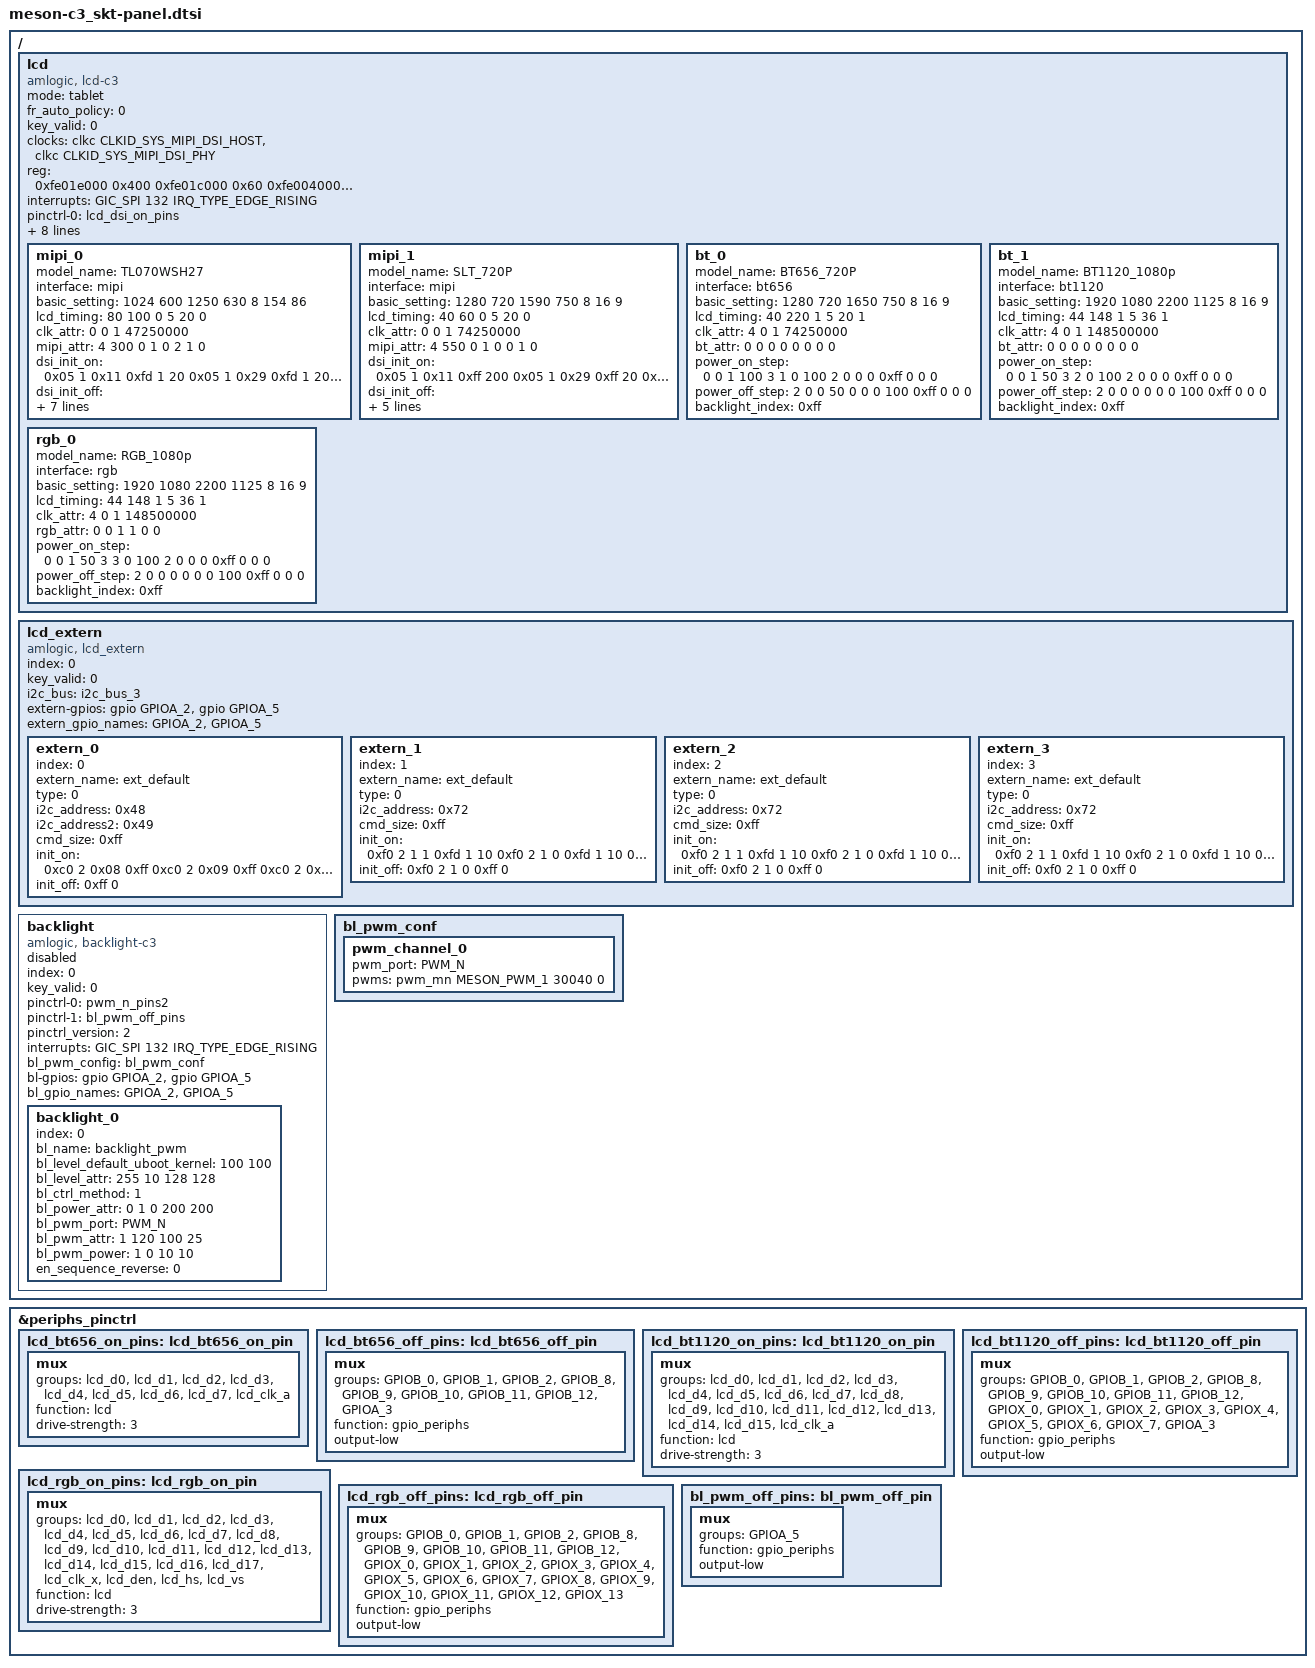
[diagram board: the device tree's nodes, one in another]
// SPDX-License-Identifier: (GPL-2.0+ OR MIT)
/*
 * Copyright (c) 2019 Amlogic, Inc. All rights reserved.
 */

/ {
	lcd: lcd {
		compatible = "amlogic, lcd-c3";
		status = "okay";
		mode = "tablet";
		fr_auto_policy = <0>; /* 0=disable, 1=enable */
		key_valid = <0>;
		clocks = <&clkc CLKID_SYS_MIPI_DSI_HOST
			&clkc CLKID_SYS_MIPI_DSI_PHY>;
		clock-names = "dsi_host_gate",
			"dsi_phy_gate";
		reg = <0xfe01e000 0x400    /* mipi-dsi host */
			0xfe01c000 0x60     /* mipi-dsi phy */
			0xfe004000 0x400>;  /* pad ctrl */
		interrupts = <GIC_SPI 132 IRQ_TYPE_EDGE_RISING>;
		interrupt-names = "vsync";
		pinctrl-names = "dsi_on","bt656_on","bt656_off",
			"bt1120_on","bt1120_off",
			"rgb_sync_de_on", "rgb_off";
		pinctrl-0 = <&lcd_dsi_on_pins>;
		pinctrl-1 = <&lcd_bt656_on_pins>;
		pinctrl-2 = <&lcd_bt656_off_pins>;
		pinctrl-3 = <&lcd_bt1120_on_pins>;
		pinctrl-4 = <&lcd_bt1120_off_pins>;
		pinctrl-5 = <&lcd_rgb_on_pins>;
		pinctrl-6 = <&lcd_rgb_off_pins>;

		/* power type:(0=cpu_gpio, 2=signal, 3=extern, 0xff=ending) */
		/* power index:(gpios_index, or extern_index, 0xff=invalid) */
		/* power value:(0=output low, 1=output high, 2=input) */
		/* power delay:(unit in ms) */
		lcd_cpu-gpios = <&gpio GPIOA_4 GPIO_ACTIVE_HIGH
			&gpio GPIOA_3 GPIO_ACTIVE_HIGH>;
		lcd_cpu_gpio_names = "GPIOA_4","GPIOA_3";

		mipi_0{
			model_name = "TL070WSH27";
			interface = "mipi";
			basic_setting = <1024 600 /*h_active, v_active*/
				1250 630 /*h_period, v_period*/
				8 /*lcd_bits*/
				154 86>; /*screen_widht, screen_height*/
			lcd_timing = <80 100 0 /*hs_width, hs_bp, hs_pol*/
				5 20 0>; /*vs_width, vs_bp, vs_pol*/
			clk_attr = <0 /*fr_adj_type(0=clk, 1=htotal, 2=vtotal)*/
				0 /*clk_ss_level */
				1 /*clk_auto_generate*/
				47250000>; /*pixel_clk(unit in Hz)*/
			mipi_attr = <4 /*lane_num*/
				300 /*bit_rate_max(MHz)*/
				0 /*factor(*100, default 0 for auto)*/
				1 /*operation_mode_init(0=video, 1=command)*/
				0 /*operation_mode_display(0=video, 1=command)*/
				2 /*
				   *video_mode_type
				   *(0=sync_pulse,1=sync_event,2=burst)
				   */
				1 /*clk_always_hs(0=disable,1=enable)*/
				0>; /*phy_switch(0=auto,1=standard,2=slow)*/

			/* dsi_init: data_type, num, data... */
			dsi_init_on = <0x05 1 0x11
					0xfd 1 20     /*delay(ms)*/
					0x05 1 0x29
					0xfd 1 20     /*delay(ms)*/
					0xff 0>; /*ending*/
			dsi_init_off = <0x05 1 0x28
					0xfd 1 10     /*delay(ms)*/
					0x05 1 0x10
					0xfd 1 10     /*delay(ms)*/
					0xff 0>; /*ending*/
			extern_init = <0xff>; /*0xff for invalid*/

			/* power step: type, index, value, delay(ms) */
			power_on_step = <
				0 0 1 100
				0 1 0 10
				0 1 1 20
				2 0 0 0
				0xff 0 0 0>; /*ending*/
			power_off_step = <
				2 0 0 50
				0 1 0 10
				0 0 0 100
				0xff 0 0 0>; /*ending*/
			backlight_index = <0>;
		};
		mipi_1{
			model_name = "SLT_720P";
			interface = "mipi";
			basic_setting = <1280 720 /*h_active, v_active*/
				1590 750 /*h_period, v_period*/
				8 /*lcd_bits*/
				16 9>; /*screen_widht, screen_height*/
			lcd_timing = <40 60 0 /*hs_width,hs_bp,hs_pol*/
				5 20 0>; /*vs_width,vs_bp,vs_pol*/
			clk_attr = <0 /*fr_adj_type(0=clock,1=htotal,2=vtotal)*/
				0 /*clk_ss_level*/
				1 /*clk_auto_generate*/
				74250000>; /*pixel_clk(unit in Hz)*/
			mipi_attr = <4 /*lane_num*/
				550 /*bit_rate_max(MHz)*/
				0 /*factor(*100, default 0 for auto)*/
				1 /*operation_mode_init(0=video, 1=command)*/
				0 /*operation_mode_display(0=video, 1=command)*/
				0 /*
				   *video_mode_type
				   *(0=sync_pulse,1=sync_event,2=burst)
				   */
				1 /*clk_always_hs(0=disable,1=enable)*/
				0>; /*phy_switch(0=auto,1=standard,2=slow)*/
				/* dsi_init: data_type, num, data... */
			dsi_init_on = <
				0x05 1 0x11
				0xff 200
				0x05 1 0x29
				0xff 20
				0xff 0xff>; /* ending flag */
			dsi_init_off = <
				0x05 1 0x28
				0xff 10
				0x05 1 0x10
				0xff 10
				0xff 0xff>; /* ending flag */
				/* extern_init: 0xff for invalid */
			extern_init = <0xff>;
				/* power step: type,index,value,delay(ms) */
			power_on_step = <
					3 0 0 100
					2 0 0 0
					0xff 0 0 0>;
			power_off_step = <
					2 0 0 0
					0xff 0 0 0>;
			backlight_index = <0xff>;
		};

		bt_0{
			model_name = "BT656_720P";
			interface = "bt656";
			basic_setting = <1280 720 /*h_active, v_active*/
				1650 750 /*h_period, v_period*/
				8 /*lcd_bits*/
				16 9>; /*screen_widht, screen_height*/
			lcd_timing = <40 220 1 /*hs_width,hs_bp,hs_pol*/
				5 20 1>; /*vs_width,vs_bp,vs_pol*/
			clk_attr = <
				4 /*fr_adj_type(0=clock,1=htotal,2=vtotal,4=hdmi_mode)*/
				0 /*clk_ss_level*/
				1 /*clk_auto_generate*/
				74250000>; /*pixel_clk(unit in Hz)*/
			bt_attr = <
				0 /*clk_phase*/
				0 /*field_type(0=progress,1=interlace)*/
				0 /*mode_422(0=left,1=right,2=average)*/
				0 /*yc_swap(0=cy,1=yc)*/
				0 /*cbcr_swap(0=cbcr,1=crcb)*/
				0 /*reserved*/
				0 /*reserved*/
				0>; /*reserved*/

			/* power step: type,index,value,delay(ms) */
			power_on_step = <
				0 0 1 100
				3 1 0 100
				2 0 0 0
				0xff 0 0 0>;
			power_off_step = <
				2 0 0 50
				0 0 0 100
				0xff 0 0 0>;
			backlight_index = <0xff>;
		};
		bt_1{
			model_name = "BT1120_1080p";
			interface = "bt1120";
			basic_setting = <
				1920 1080 /*h_active, v_active*/
				2200 1125 /*h_period, v_period*/
				8      /*lcd_bits*/
				16 9>; /*screen_widht, screen_height*/
			lcd_timing = <
				44 148 1   /*hs_width, hs_bp, hs_pol*/
				5  36  1>; /*vs_width, vs_bp, vs_pol*/
			clk_attr = <
				4 /*fr_adj_type(0=clk,1=htotal,2=vtotal,4=hdmi_mode)*/
				0 /*clk_ss_level */
				1 /*clk_auto_generate*/
				148500000>; /*pixel_clk(unit in Hz)*/
			bt_attr = <
				0 /*clk_phase*/
				0 /*field_type(0=progress,1=interlace)*/
				0 /*mode_422(0=left,1=right,2=average)*/
				0 /*yc_swap(0=cy,1=yc)*/
				0 /*cbcr_swap(0=cbcr,1=crcb)*/
				0 /*reserved*/
				0 /*reserved*/
				0>; /*reserved*/

			/* power step: type, index, value, delay(ms) */
			power_on_step = <
				0 0 1 50 /*panel power on*/
				3 2 0 100
				2 0 0 0   /*signal enable*/
				0xff 0 0 0>; /*ending*/
			power_off_step = <
				2 0 0 0 /*signal disable*/
				0 0 0 100 /*panel power off*/
				0xff 0 0 0>; /*ending*/
			backlight_index = <0xff>;
		};

		rgb_0{
			model_name = "RGB_1080p";
			interface = "rgb";
			basic_setting = <
				1920 1080 /*h_active, v_active*/
				2200 1125 /*h_period, v_period*/
				8      /*lcd_bits*/
				16 9>; /*screen_widht, screen_height*/
			lcd_timing = <
				44 148 1   /*hs_width, hs_bp, hs_pol*/
				5  36  1>; /*vs_width, vs_bp, vs_pol*/
			clk_attr = <
				4 /*fr_adj_type(0=clk,1=htotal,2=vtotal,4=hdmi_mode)*/
				0 /*clk_ss_level */
				1 /*clk_auto_generate*/
				148500000>; /*pixel_clk(unit in Hz)*/
			rgb_attr = <
				0 /*rgb type*/
				0 /*clk_pol*/
				1 /*de_valid*/
				1 /*sync_valid*/
				0 /*rb_swap*/
				0>; /*bit_swap*/

			/* power step: type, index, value, delay(ms) */
			power_on_step = <
				0 0 1 50 /*panel power on*/
				3 3 0 100
				2 0 0 0   /*signal enable*/
				0xff 0 0 0>; /*ending*/
			power_off_step = <
				2 0 0 0 /*signal disable*/
				0 0 0 100 /*panel power off*/
				0xff 0 0 0>; /*ending*/
			backlight_index = <0xff>;
		};
	};

	lcd_extern{
		compatible = "amlogic, lcd_extern";
		status = "okay";
		index = <0>;
		key_valid = <0>;
		i2c_bus = "i2c_bus_3";

		extern-gpios = <&gpio GPIOA_2 GPIO_ACTIVE_HIGH
			&gpio GPIOA_5 GPIO_ACTIVE_HIGH>;
		extern_gpio_names = "GPIOA_2","GPIOA_5";

		extern_0{
			index = <0>;
			extern_name = "ext_default";/*LT8912*/
			status = "okay";
			type = <0>; /* 0=i2c, 1=spi, 2=mipi */
			i2c_address = <0x48>; /*7bit i2c_addr*/
			i2c_address2 = <0x49>;
			cmd_size = <0xff>;
			init_on = <
				0xc0 2 0x08 0xff
				0xc0 2 0x09 0xff
				0xc0 2 0x0a 0xff
				0xc0 2 0x0b 0x7c
				0xc0 2 0x0c 0xff
				0xfd 1 10

				0xc0 2 0x31 0xa1
				0xc0 2 0x32 0xa1
				0xc0 2 0x33 0x03
				0xc0 2 0x37 0x00
				0xc0 2 0x38 0x22
				0xc0 2 0x60 0x82
				0xfd 1 10

				0xc0 2 0x39 0x45
				0xc0 2 0x3b 0x00
				0xfd 1 10

				0xc0 2 0x44 0x31
				0xc0 2 0x55 0x44
				0xc0 2 0x57 0x01
				0xc0 2 0x5a 0x02
				0xfd 1 10

				0xc0 2 0x3e 0xc6
				0xc0 2 0x41 0x7c
				0xfd 1 10

				0xc1 2 0x10 0x04
				0xc1 2 0x11 0x04
				0xc1 2 0x12 0x04
				0xc1 2 0x13 0x00
				0xc1 2 0x14 0x00
				0xc1 2 0x15 0x00
				0xc1 2 0x1a 0x03
				0xc1 2 0x1b 0x03
				0xfd 1 20

				0xc1 2 0x18 0x28
				0xc1 2 0x19 0x05
				0xc1 2 0x1c 0x00
				0xc1 2 0x1d 0x05
				0xc1 2 0x2f 0x0c
				0xc1 2 0x34 0x72
				0xc1 2 0x35 0x06
				0xc1 2 0x36 0xee
				0xc1 2 0x37 0x02
				0xc1 2 0x38 0x14
				0xc1 2 0x39 0x00
				0xc1 2 0x3a 0x05
				0xc1 2 0x3b 0x00
				0xc1 2 0x3c 0xdc
				0xc1 2 0x3d 0x00
				0xc1 2 0x3e 0x6e
				0xc1 2 0x3f 0x00
				0xfd 1 10

				0xc0 2 0x03 0x7f
				0xfd 1 200
				0xc0 2 0x03 0xff
				0xfd 1 200

				0xc1 2 0x4e 0x6A
				0xc1 2 0x4f 0x4D
				0xc1 2 0x50 0xF3
				0xc1 2 0x51 0x80
				0xc1 2 0x1f 0x90
				0xc1 2 0x20 0x01
				0xc1 2 0x21 0x68
				0xc1 2 0x22 0x01
				0xc1 2 0x23 0x5E
				0xc1 2 0x24 0x01
				0xc1 2 0x25 0x54
				0xc1 2 0x26 0x01
				0xc1 2 0x27 0x90
				0xc1 2 0x28 0x01
				0xc1 2 0x29 0x68
				0xc1 2 0x2a 0x01
				0xc1 2 0x2b 0x5E
				0xc1 2 0x2c 0x01
				0xc1 2 0x2d 0x54
				0xc1 2 0x2e 0x01
				0xc1 2 0x42 0x64
				0xc1 2 0x43 0x00
				0xc1 2 0x44 0x04
				0xc1 2 0x45 0x00
				0xc1 2 0x46 0x59
				0xc1 2 0x47 0x00
				0xc1 2 0x48 0xf2
				0xc1 2 0x49 0x06
				0xc1 2 0x4a 0x00
				0xc1 2 0x4b 0x72
				0xc1 2 0x4c 0x45
				0xc1 2 0x4d 0x00
				0xc1 2 0x52 0x08
				0xc1 2 0x53 0x00
				0xc1 2 0x54 0xb2
				0xc1 2 0x55 0x00
				0xc1 2 0x56 0xe4
				0xc1 2 0x57 0x0d
				0xc1 2 0x58 0x00
				0xc1 2 0x59 0xe4
				0xc1 2 0x5a 0x8a
				0xc1 2 0x5b 0x00
				0xc1 2 0x5c 0x34
				0xc1 2 0x1e 0x4f
				0xc1 2 0x51 0x00
				0xff 0>; /*ending*/
			init_off = <
				0xff 0>; /*ending*/
		};

		extern_1{
			index = <1>;
			extern_name = "ext_default";/*LT8616: bt656*/
			status = "okay";
			type = <0>; /* 0=i2c, 1=spi, 2=mipi */
			i2c_address = <0x72>; /*7bit i2c_addr*/
			cmd_size = <0xff>;
			init_on = <
				0xf0 2 1 1  //reset high
				0xfd 1 10   //delay 10ms
				0xf0 2 1 0  //reset low
				0xfd 1 10   //delay 10ms
				0xf0 2 1 1  //reset high
				0xfd 1 10   //delay 10ms
				0xff 0>; /*ending*/
			init_off = <
				0xf0 2 1 0  //reset low
				0xff 0>; /*ending*/
		};

		extern_2{
			index = <2>;
			extern_name = "ext_default";/*LT8616: bt1120*/
			status = "okay";
			type = <0>; /* 0=i2c, 1=spi, 2=mipi */
			i2c_address = <0x72>; /*7bit i2c_addr*/
			cmd_size = <0xff>;
			init_on = <
				0xf0 2 1 1  //reset high
				0xfd 1 10   //delay 10ms
				0xf0 2 1 0  //reset low
				0xfd 1 10   //delay 10ms
				0xf0 2 1 1  //reset high
				0xfd 1 10   //delay 10ms
				0xff 0>; /*ending*/
			init_off = <
				0xf0 2 1 0  //reset low
				0xff 0>; /*ending*/
		};

		extern_3{
			index = <3>;
			extern_name = "ext_default";/*LT8616: rgb*/
			status = "okay";
			type = <0>; /* 0=i2c, 1=spi, 2=mipi */
			i2c_address = <0x72>; /*7bit i2c_addr*/
			cmd_size = <0xff>;
			init_on = <
				0xf0 2 1 1  //reset high
				0xfd 1 10   //delay 10ms
				0xf0 2 1 0  //reset low
				0xfd 1 10   //delay 10ms
				0xf0 2 1 1  //reset high
				0xfd 1 10   //delay 10ms
				0xff 0>; /*ending*/
			init_off = <
				0xf0 2 1 0  //reset low
				0xff 0>; /*ending*/
		};
	};

	backlight{
		compatible = "amlogic, backlight-c3";
		status = "disabled";
		index = <0>;
		key_valid = <0>;
		pinctrl-names = "pwm_on", "pwm_off";
		pinctrl-0 = <&pwm_n_pins2>;
		pinctrl-1 = <&bl_pwm_off_pins>;
		pinctrl_version = <2>; /* for uboot */
		interrupts = <GIC_SPI 132 IRQ_TYPE_EDGE_RISING>;
		interrupt-names = "vsync";
		bl_pwm_config = <&bl_pwm_conf>;

		/* pwm port: PWM_A, PWM_B, PWM_C, PWM_D, PWM_E, PWM_F, PWM_VS*/
		/* power index:(point gpios_index, 0xff=invalid) */
		/* power value:(0=output low, 1=output high, 2=input) */
		/* power delay:(unit in ms) */
		bl-gpios = <&gpio GPIOA_2 GPIO_ACTIVE_HIGH
			&gpio GPIOA_5 GPIO_ACTIVE_HIGH>;
		bl_gpio_names = "GPIOA_2","GPIOA_5";

		backlight_0{
			index = <0>;
			bl_name = "backlight_pwm";
			bl_level_default_uboot_kernel = <100 100>;
			bl_level_attr = <255 10 /*max, min*/
				128 128>; /*mid, mid_mapping*/
			bl_ctrl_method = <1>; /*1=pwm,2=pwm_combo,3=ldim*/
			bl_power_attr = <0 /*en_gpio_index*/
				1 0 /*on_value, off_value*/
				200 200>; /*on_delay(ms), off_delay(ms)*/
			bl_pwm_port = "PWM_N";
			bl_pwm_attr = <1 /*pwm_method(0=negative, 1=positvie)*/
				120 /*pwm_freq(pwm:Hz, pwm_vs:multiple of vs)*/
				100 25>; /*duty_max(%), duty_min(%)*/
			bl_pwm_power = <1 0 /*pwm_gpio_index, pwm_gpio_off*/
				10 10>; /*pwm_on_delay(ms), pwm_off_delay(ms)*/
			en_sequence_reverse = <0>; /* 1 for reverse */
		};
	};

	bl_pwm_conf:bl_pwm_conf{
		pwm_channel_0 {
			pwm_port = "PWM_N";
			pwms = <&pwm_mn MESON_PWM_1 30040 0>;
		};
	};
}; /* end of / */

&periphs_pinctrl {
	lcd_bt656_on_pins:lcd_bt656_on_pin {
		mux {
			groups = "lcd_d0","lcd_d1","lcd_d2","lcd_d3",
				"lcd_d4","lcd_d5","lcd_d6","lcd_d7",
				"lcd_clk_a";
			function = "lcd";
			drive-strength = <3>;
		};
	};

	lcd_bt656_off_pins:lcd_bt656_off_pin {
		mux {
			groups = "GPIOB_0","GPIOB_1","GPIOB_2","GPIOB_8",
				"GPIOB_9","GPIOB_10","GPIOB_11","GPIOB_12",
				"GPIOA_3";
			function = "gpio_periphs";
			output-low;
		};
	};

	lcd_bt1120_on_pins:lcd_bt1120_on_pin {
		mux {
			groups = "lcd_d0","lcd_d1","lcd_d2","lcd_d3",
				"lcd_d4","lcd_d5","lcd_d6","lcd_d7",
				"lcd_d8","lcd_d9","lcd_d10","lcd_d11",
				"lcd_d12","lcd_d13","lcd_d14","lcd_d15",
				"lcd_clk_a";
			function = "lcd";
			drive-strength = <3>;
		};
	};

	lcd_bt1120_off_pins:lcd_bt1120_off_pin {
		mux {
			groups = "GPIOB_0","GPIOB_1","GPIOB_2","GPIOB_8",
				"GPIOB_9","GPIOB_10","GPIOB_11","GPIOB_12",
				"GPIOX_0","GPIOX_1","GPIOX_2","GPIOX_3",
				"GPIOX_4","GPIOX_5","GPIOX_6","GPIOX_7",
				"GPIOA_3";
			function = "gpio_periphs";
			output-low;
		};
	};

	lcd_rgb_on_pins:lcd_rgb_on_pin {
		mux {
			groups = "lcd_d0","lcd_d1","lcd_d2","lcd_d3",
				"lcd_d4","lcd_d5","lcd_d6","lcd_d7",
				"lcd_d8","lcd_d9","lcd_d10","lcd_d11",
				"lcd_d12","lcd_d13","lcd_d14","lcd_d15",
				"lcd_d16", "lcd_d17", "lcd_clk_x",
				"lcd_den", "lcd_hs", "lcd_vs";
			function = "lcd";
			drive-strength = <3>;
		};
	};

	lcd_rgb_off_pins:lcd_rgb_off_pin {
		mux {
			groups = "GPIOB_0","GPIOB_1","GPIOB_2","GPIOB_8",
				"GPIOB_9","GPIOB_10","GPIOB_11","GPIOB_12",
				"GPIOX_0","GPIOX_1","GPIOX_2","GPIOX_3",
				"GPIOX_4","GPIOX_5","GPIOX_6","GPIOX_7",
				"GPIOX_8","GPIOX_9","GPIOX_10","GPIOX_11",
				"GPIOX_12","GPIOX_13";
			function = "gpio_periphs";
			output-low;
		};
	};

	bl_pwm_off_pins:bl_pwm_off_pin {
		mux {
			groups = "GPIOA_5";
			function = "gpio_periphs";
			output-low;
		};
	};
};

